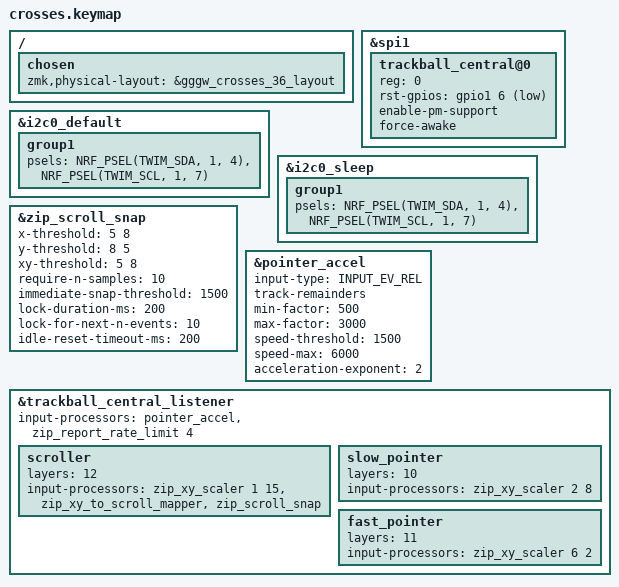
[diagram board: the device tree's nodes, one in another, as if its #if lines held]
#include <behaviors.dtsi>
#define CONFIG_WIRELESS
#define CONFIG_TRACKBALL

#if ! CROSSES54==y
#define ZMK_BASE_LAYER(name, LT, RT, LM, RM, LB, RB, LH, RH)  \
    ZMK_LAYER(                                                                 \
        name,                                                                  \
                 LT RT                                                         \
                 LM RM                                                         \
                 LB RB                                                         \
       SMART_NUM LH RH SMART_SHIFT                                             \
    )

#include "zmk-helpers/key-labels/36.h"


#define KEYS_L LT0 LT1 LT2 LT3 LT4 LM0 LM1 LM2 LM3 LM4 LB0 LB1 LB2 LB3 LB4 // Left-hand keys.
#define KEYS_R RT0 RT1 RT2 RT3 RT4 RM0 RM1 RM2 RM3 RM4 RB0 RB1 RB2 RB3 RB4 // Right-hand keys.
#define THUMBS LH2 LH1 LH0 RH0 RH1 RH2 // Thumb keys.
#define PM_KEY &soft_off

/ {
    chosen {
        zmk,physical-layout = &gggw_crosses_36_layout;
    };
};

#else

#define ZMK_BASE_LAYER(name, LT, RT, LM, RM, LB, RB, LH, RH)  \
    ZMK_LAYER(                                                                 \
         name,                                                                  \
         &kp GRAVE &kp N1 &kp N2 &kp N3 &kp N4 &kp N5    &kp N6 &kp N7 &kp N8 &kp N9 &kp N0 &kp BSPC  \
         &kp TAB   LT RT &kp BSPC                                                         \
         &kp ESC   LM RM &kp SQT                                                         \
         &kp LCTRL LB RB &kp RSFT                                                         \
                SMART_NUM LH RH SMART_SHIFT                   \
    )

#include "zmk-helpers/key-labels/54.h"


#define KEYS_L LN0 LN1 LN2 LN3 LN4 LN5 LT0 LT1 LT2 LT3 LT4 LM0 LM1 LM2 LM3 LM4 LB0 LB1 LB2 LB3 LB4 // Left-hand keys.
#define KEYS_R RN0 RN1 RN2 RN3 RN4 RN5 RT0 RT1 RT2 RT3 RT4 RM0 RM1 RM2 RM3 RM4 RB0 RB1 RB2 RB3 RB4 // Right-hand keys.
#define THUMBS LH2 LH1 LH0 RH0 RH1 RH2 // Thumb keys.
#define PM_KEY &soft_off

/ {
    chosen {
        zmk,physical-layout = &gggw_crosses_54_layout;
    };
};
#endif

&spi1 {
//	/delete-node/ trackball_central@0;
	/delete-node/ trackball_peripheral@0;
	trackball_central@0 {
		reg = <0>;
		rst-gpios = <&gpio1 6  GPIO_ACTIVE_LOW>;
		enable-pm-support;
		force-awake;
    };
};

&i2c0_default {
	group1 {
            psels = <NRF_PSEL(TWIM_SDA, 1, 4)>,
                <NRF_PSEL(TWIM_SCL, 1, 7)>;
	};
};
&i2c0_sleep {
	group1 {
            psels = <NRF_PSEL(TWIM_SDA, 1, 4)>,
                <NRF_PSEL(TWIM_SCL, 1, 7)>;
	};
};

// /delete-node/ &trackball_central_listener;
// /delete-node/ &trackball_peripheral_split;
//     /delete-node/ &trackball_peripheral_listener;

#include <scroll-snap.dtsi>
#include <input/processors/report_rate_limit.dtsi>
#include <behaviors/input_gestures_accel.dtsi>
&zip_scroll_snap {
    x-threshold = <5 8>;
    y-threshold = <8 5>;
    xy-threshold = <5 8>;

    require-n-samples = <10>;
    immediate-snap-threshold = <1500>;
    lock-duration-ms = <200>;
    lock-for-next-n-events = <10>;
    idle-reset-timeout-ms = <200>;
};

&pointer_accel {
    input-type = <INPUT_EV_REL>;  // For relative input devices
    track-remainders;             // Accumulate fractional movements
    min-factor = <500>;          //  at very slow speeds
    max-factor = <3000>;         // 3.0x at fast speeds
    speed-threshold = <1500>;     // 1200 counts/sec for 1x
    speed-max = <6000>;          // 6000 counts/sec for max accel
    acceleration-exponent = <2>;  // Quadratic acceleration curve
};

&trackball_central_listener {
		input-processors = <
                                       // &zip_xy_scaler 1 1
                                       &pointer_accel
                                       &zip_report_rate_limit 4
        >;

		scroller: scroller {
			layers           = <12>;
			input-processors = <
									   &zip_xy_scaler 1 15                              // Scales the scroll speed
									   &zip_xy_to_scroll_mapper                         // Converts XY movement to scroll events
									   &zip_scroll_snap
									   //&zip_scroll_transform (INPUT_TRANSFORM_Y_INVERT) // Inverts the scroll direction
							   >;
		};

		slow_pointer: slow_pointer {
			layers           = <10>;
			input-processors = <&zip_xy_scaler 2 8>;
		};

		fast_pointer: fast_pointer {
			layers           = <11>;
			input-processors = <&zip_xy_scaler 6 2>;
		};
};

#include "nano_led.dtsi"
#include "base.keymap"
